VERSION ""

NS_ :

BS_:
BU_: VCU
BO_ 513 Torque_Command: 8 VCU
   SG_ CommandFlag : 0|8@1+ (1,0) [144|144] "" VCU
   SG_ TorqueRequest : 8|16@1+ (1,0) [-32768|32767] "torque_units" VCU

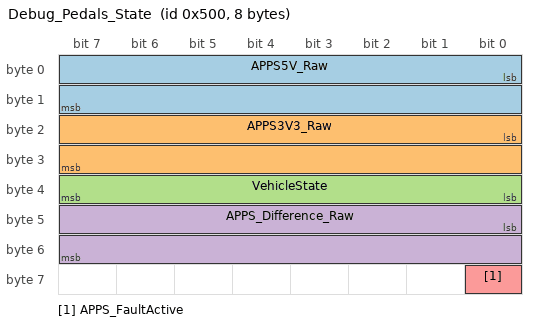
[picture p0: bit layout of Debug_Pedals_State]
BO_ 1280 Debug_Pedals_State: 8 VCU
   SG_ APPS5V_Raw : 0|16@1+ (1,0) [0|1023] "ADC_units" VCU
   SG_ APPS3V3_Raw : 16|16@1+ (1,0) [0|675] "ADC_units" VCU
   SG_ VehicleState : 32|8@1+ (1,0) [0|3] "" VCU
   SG_ APPS_Difference_Raw : 40|16@1+ (0.0977,0) [0|1023] "" VCU
   SG_ APPS_FaultActive : 56|1@1+ (1,0) [0|1] "" VCU

BA_DEF_ BO_ "GenMsgBackgroundColor" STRING ;
BA_DEF_ BO_ "GenMsgForegroundColor" STRING ;
BA_DEF_ BO_ "filterlabeling" INT 0 0;
BA_DEF_DEF_ "GenMsgBackgroundColor" "#ffffff";
BA_DEF_DEF_ "GenMsgForegroundColor" "#000000";
BA_DEF_DEF_ "filterlabeling" 1;
VAL_ 1280 VehicleState 0 "INIT" 1 "STARTIN" 2 "BUZZIN" 3 "DRIVIN";
